# R7FA8D1BH register map
Vendor: Renesas; Series: RA8; File version: 1.2
CPU: CM85 r0p0, little endian, MPU, FPU, VTOR, 4 interrupt priority bits
Registers are 32-bit, read-write, reset 0x0 unless marked. A register's access mark holds for its fields unless they carry their own. Offsets are from the block's base; [hi:lo] are bit positions; {n}, {i} and the like mark numbered series; 'fields as' and 'values as' point back to an identical list.

## xSPI — eXpanded SPI
Base 0x40268000
Same registers: xSPI_NS 0x50268000
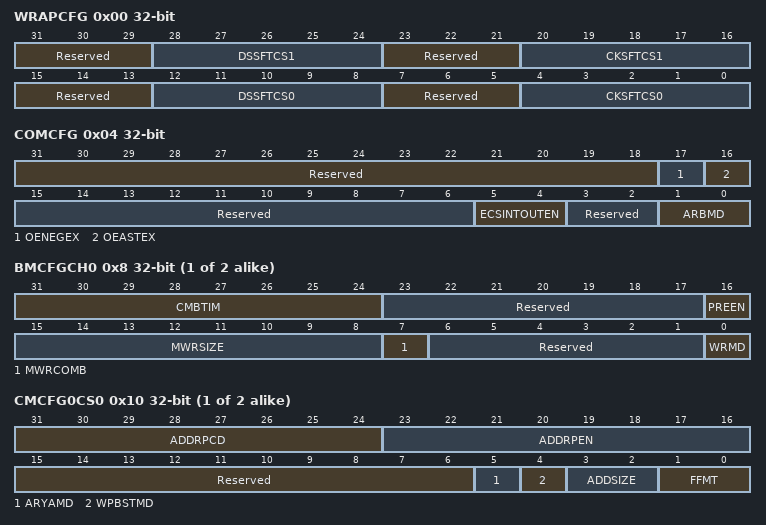
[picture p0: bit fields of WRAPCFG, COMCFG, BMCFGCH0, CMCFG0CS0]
0x00 WRAPCFG — xSPI Wrapper Configuration register
  [31:29] Reserved — These bits are read as 000. The write value should be 000.
  [28:24] DSSFTCS1 — DS shift for slave1
  [23:21] Reserved — These bits are read as 000. The write value should be 000.
  [20:16] CKSFTCS1 — CK shift for slave1
  [15:13] Reserved — These bits are read as 000. The write value should be 000.
  [12:8] DSSFTCS0 — DS shift for slave0
    0=No shift; 1=Add a delay of 1 cell
  [7:5] Reserved — These bits are read as 000. The write value should be 000.
  [4:0] CKSFTCS0 — CK shift for slave0
    0=No shift; 1=Add a delay of 1 cell
0x04 COMCFG — xSPI Common Configuration register
  [31:18] Reserved — These bits are read as 00000000000000. The write value should be 00000000000000.
  [17] OENEGEX — Output Enable Negating extension
    0=No extend 1cycle Output enable; 1=Extend 1cycle Output enable
  [16] OEASTEX — Output Enable Asserting extension
    values as OENEGEX
  [15:6] Reserved — These bits are read as 0000000000. The write value should be 0000000000.
  [5:4] ECSINTOUTEN — ECS/INT Output Enable
  [3:2] Reserved — These bits are read as 00. The write value should be 00.
  [1:0] ARBMD — Channel arbitration mode
{0x8+4i} BMCFGCH{i} (i=0..1) — xSPI Bridge Map Configuration register ch{i}
  [31:24] CMBTIM — Combination timer
    0=00h (means disabling the combination timer. When the timer is)
  [23:17] Reserved — These bits are read as 0000000. The write value should be 0000000.
  [16] PREEN — Prefetch enable
    0=Disable prefetch function; 1=Enable prefetch function
  [15:8] MWRSIZE — Memory Write Size
  [7] MWRCOMB — Memory Write Combination mode
    0=Disable combination mode; 1=Enable combination mode
  [6:1] Reserved — These bits are read as 000000. The write value should be 000000.
  [0] WRMD — AHB Write Response mode
    0=Return response after storing to Internal Write Buffer; 1=Return response after issuing write transaction to xSPI bus
{0x10+0x10*i} CMCFG0CS{i} (i=0..1) — xSPI Command Map Configuration register 0 cs{i}
  [31:24] ADDRPCD — Address Replace Code
  [23:16] ADDRPEN — Address Replace Enable
    0=No replacement (xSPI frame address field is same as AHB address); 1=Replacement
  [15:6] Reserved — These bits are read as 0000000000. The write value should be 0000000000.
  [5] ARYAMD — Array address mode
    0=Normal address mode; 1=Array address mode
  [4] WPBSTMD — Wrapping burst mode
    0=separate xSPI transfer at the wrapping address boundary; 1=not separate xSPI transfer at the wrapping address boundary
  [3:2] ADDSIZE — Address size
    0=1byte (256Byte address space); 1=2byte (64KByte address space)
  [1:0] FFMT — Frame format
    0=Normal format: Command 1byte, Address ADDSIZE, Data up to AHB transaction; 1=8D-8D-8D profile 1.0 format: Command 2byte, Address ADDSIZE, Data up to AHB transaction
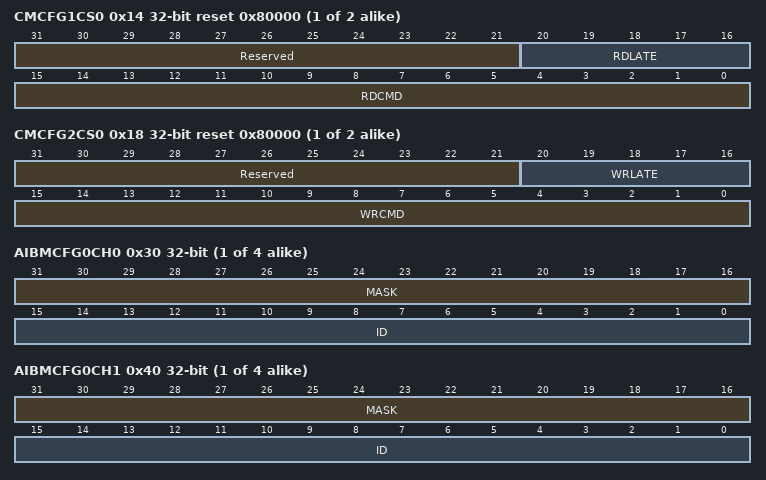
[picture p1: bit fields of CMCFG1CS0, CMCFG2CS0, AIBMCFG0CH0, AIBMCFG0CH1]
{0x14+0x10*i} CMCFG1CS{i} (i=0..1) reset 0x80000 — xSPI Command Map Configuration register 1 cs{i}
  [31:21] Reserved — These bits are read as 00000000000. The write value should be 00000000000.
  [20:16] RDLATE — Read latency cycle
    0=No latency
  [15:0] RDCMD — Read command
{0x18+0x10*i} CMCFG2CS{i} (i=0..1) reset 0x80000 — xSPI Command Map Configuration register 2 cs{i}
  [31:21] Reserved — These bits are read as 00000000000. The write value should be 00000000000.
  [20:16] WRLATE — Write latency cycle
    0=No latency
  [15:0] WRCMD — Write command
{0x30+4i} AIBMCFG{i}CH0 (i=0..3) — xSPI AXI ID Bridge Map Config {i} ch0
  [31:16] MASK — AXI ID to Chx Map Mask
  [15:0] ID — AXI ID to Chx Map Value
{0x40+4i} AIBMCFG{i}CH1 (i=0..3) — xSPI AXI ID Bridge Map Config {i} ch1
  fields as AIBMCFG0CH0
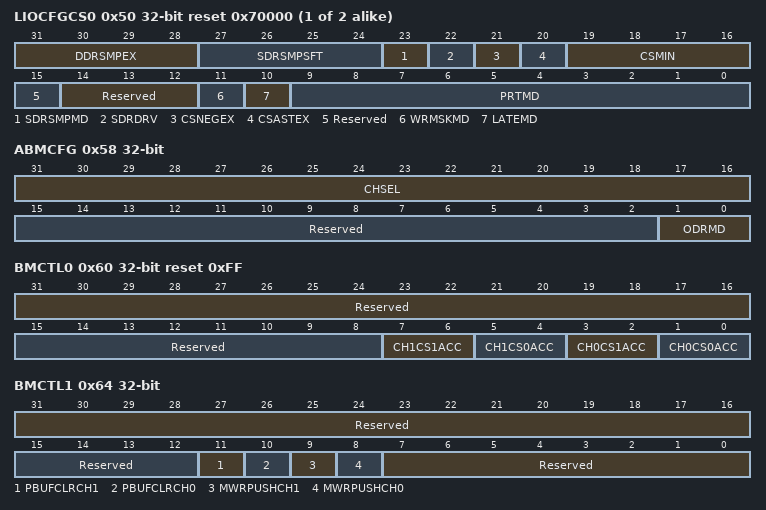
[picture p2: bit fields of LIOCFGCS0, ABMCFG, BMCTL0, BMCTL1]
{0x50+4i} LIOCFGCS{i} (i=0..1) reset 0x70000 — xSPI Link I/O Configuration register cs{i}
  [31:28] DDRSMPEX — DDR sampling window extend
    0=Expand no cycle; 1=Expand 1 cycle; other=others (Reserved)
  [27:24] SDRSMPSFT — SDR Sampling window shift
    0=Sample w/o delay; 1=Sample at 1 cycle delay; other=others (Reserved)
  [23] SDRSMPMD — SDR Sampling mode
    0=Samples data input at falling-edge; 1=Samples data input at rising-edge
  [22] SDRDRV — SDR driving timing
    0=Drive at 1/2 cycle before CK rising-edge; 1=Drive at CK rising-edge
  [21] CSNEGEX — CS negating extension
    0=No extension; 1=Extend 1 cycle
  [20] CSASTEX — CS asserting extension
    0=No extension; 1=Extend 1 cycle
  [19:16] CSMIN — CS minimum idle term
    0=1 cycle
  [15] Reserved — This bit is read as 0. The write value should be 0.
  [14:12] Reserved — These bits are read as 000. The write value should be 000.
  [11] WRMSKMD — Write mask mode
    0=Write mask disable; 1=Write mask enable
  [10] LATEMD — Latency mode
    0=Configurable latency; 1=Variable latency
  [9:0] PRTMD — Protocol mode
    0=0_000_000_000b (1S-1S-1S); 0x3B2=1_110_110_010b (4S-4D-4D); 0x3FF=1_111_111_111b (8D-8D-8D); 0x2FF=1_011_111_111b (8D-8D-8S); 72=0_001_001_000b (1S-2S-2S); 73=0_001_001_001b (2S-2S-2S); 144=0_010_010_000b (1S-4S-4S); 146=0_010_010_010b (4S-4S-4S); other=others (Reserved)
0x58 ABMCFG — xSPI AXI Bridge Map Config
  [31:16] CHSEL — AXI ID to Bridge Channel Select
  [15:2] Reserved — These bits are read as 00000000000000. The write value should be 00000000000000.
  [1:0] ODRMD — AXI Transfer Ordering Mode
0x60 BMCTL0 reset 0xFF — xSPI Bridge Map Control register 0
  [31:16] Reserved — These bits are read as 0000000000000000. The write value should be 0000000000000000.
  [15:8] Reserved — These bits are read as 00000000. The write value should be 00000000.
  [7:6] CH1CS1ACC — System bus ch1 to slave1 memory area access enable
  [5:4] CH1CS0ACC — System bus ch1 to slave0 memory area access enable
  [3:2] CH0CS1ACC — System bus ch0 to slave1 memory area access enable
  [1:0] CH0CS0ACC — System bus ch0 to slave0 memory area access enable
0x64 BMCTL1 wo — xSPI Bridge Map Control register 1
  [31:16] Reserved — The write value should be 0000000000000000.
  [15:12] Reserved — The write value should be 0000.
  [11] PBUFCLRCH1 — Prefetch Buffer clear for ch1
  [10] PBUFCLRCH0 — Prefetch Buffer clear for ch0
    0=No command; 1=Clear request
  [9] MWRPUSHCH1 — Memory Write Data Push for ch1
  [8] MWRPUSHCH0 — Memory Write Data Push for ch0
    0=No command; 1=Push request
  [7:0] Reserved — The write value should be 00000000.
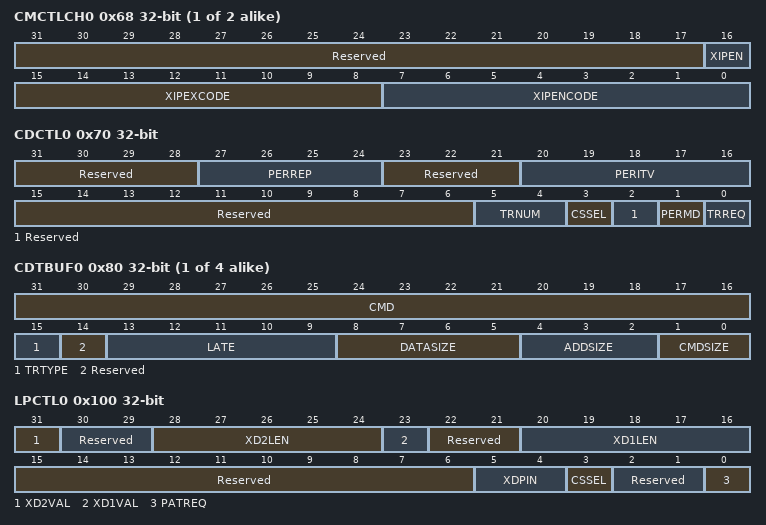
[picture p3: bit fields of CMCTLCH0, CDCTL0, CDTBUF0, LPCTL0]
{0x68+4i} CMCTLCH{i} (i=0..1) — xSPI Command Map Control register ch{i}
  [31:17] Reserved — These bits are read as 000000000000000. The write value should be 000000000000000.
  [16] XIPEN — XiP mode enable
    0=Disable XiP mode; 1=Enable XiP mode
  [15:8] XIPEXCODE — XiP mode exit code
  [7:0] XIPENCODE — XiP mode enter code
0x70 CDCTL0 — xSPI Command Manual Control register 0
  [31:28] Reserved — These bits are read as 0000. The write value should be 0000.
  [27:24] PERREP — Periodic transaction repeat
  [23:21] Reserved — These bits are read as 000. The write value should be 000.
  [20:16] PERITV — Periodic transaction interval
    0=2(=2^1) cycles; 1=4(=2^2) cycles
  [15:6] Reserved — These bits are read as 0000000000. The write value should be 0000000000.
  [5:4] TRNUM — Transaction number
    0=Issue 1 command (using command buffer0); 1=Issue 2 commands (using command buffer0-1)
  [3] CSSEL — Chip select
    0=CS0; 1=CS1
  [2] Reserved — This bit is read as 0. The write value should be 0.
  [1] PERMD — Periodic mode
    0=Direct manual-command mode; 1=Periodic manual-command mode
  [0] TRREQ — Transaction request
    0=No transaction; 1=Request transaction
0x74 CDCTL1 — xSPI Command Manual Control register 1
  [31:0] PEREXP — Periodic transaction expected value
0x78 CDCTL2 — xSPI Command Manual Control register 2
  [31:0] PERMSK — Periodic transaction masked value
{0x80+0x10*i} CDTBUF{i} (i=0..3) — xSPI Command Manual Type buf{i}
  [31:16] CMD — Command (1-2byte)
  [15] TRTYPE — Transaction Type
    0=Read transaction (Readout from memory device); 1=Not read transaction
  [14] Reserved — This bit is read as 0. The write value should be 0.
  [13:9] LATE — Latency cycle
    0=No latency
  [8:5] DATASIZE — Write/Read Data Size
    0=0 byte (No data phase); other=others (Reserved)
  [4:2] ADDSIZE — Address size
    0=0byte (No address phase); other=others (Reserved)
  [1:0] CMDSIZE — Command Size
    0=0byte (No command phase)
{0x84+0x10*i} CDABUF{i} (i=0..3) — xSPI Command Manual Address buf{i}
  [31:0] ADD — Address
{0x88+0x10*i} CDD0BUF{i} (i=0..3) — xSPI Command Manual Data 0 buf{i}
  [31:0] DATA — Write/Read Data
{0x8C+0x10*i} CDD1BUF{i} (i=0..3) — xSPI Command Manual Data 1 buf{i}
  [31:0] DATA — Write/Read Data
0x100 LPCTL0 — xSPI Link Pattern Control register 0
  [31] XD2VAL — XiP Disable pattern 2nd phase value
    0=Low drive; 1=High drive
  [30:29] Reserved — These bits are read as 00. The write value should be 00.
  [28:24] XD2LEN — XiP Disable pattern 2nd phase length
    0=0 cycle
  [23] XD1VAL — XiP Disable pattern 1st phase value
    0=Low drive; 1=High drive
  [22:21] Reserved — These bits are read as 00. The write value should be 00.
  [20:16] XD1LEN — XiP Disable pattern 1st phase length
    0=0 cycle
  [15:6] Reserved — These bits are read as 0000000000. The write value should be 0000000000.
  [5:4] XDPIN — XiP Disable pattern pin
    0=1pin; 1=2pin
  [3] CSSEL — Chip select
    0=slave0 (CS0); 1=slave1 (CS1)
  [2:1] Reserved — These bits are read as 00. The write value should be 00.
  [0] PATREQ — Pattern request
    0=No request XiP Disable pattern; 1=Request XiP Disable pattern
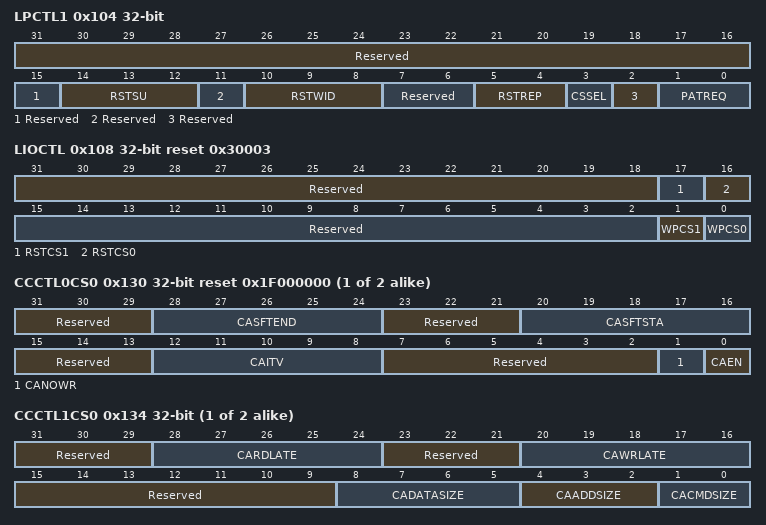
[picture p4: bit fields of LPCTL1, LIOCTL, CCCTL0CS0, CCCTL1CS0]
0x104 LPCTL1 — xSPI Link Pattern Control register 1
  [31:16] Reserved — These bits are read as 0000000000000000. The write value should be 0000000000000000.
  [15] Reserved — This bit is read as 0. The write value should be 0.
  [14:12] RSTSU — Reset pattern data output setup time
    0=1 cycle
  [11] Reserved — This bit is read as 0. The write value should be 0.
  [10:8] RSTWID — Reset pattern width
    0=2(=2^1) cycles; 1=4(=2^2) cycles
  [7:6] Reserved — These bits are read as 00. The write value should be 00.
  [5:4] RSTREP — Reset pattern repeat
    0=4 times (Specified on Reset Signaling Protocol); 1=5 times
  [3] CSSEL — Chip select
    0=slave0 (CS0); 1=slave1 (CS1)
  [2] Reserved — This bit is read as 0. The write value should be 0.
  [1:0] PATREQ — Pattern request
    0=No request; 1=Request Reset pattern; 2=Request CS only pattern
0x108 LIOCTL reset 0x30003 — xSPI Link I/O Control register
  [31:18] Reserved — These bits are read as 00000000000000. The write value should be 00000000000000.
  [17] RSTCS1 — Reset drive for slave1
  [16] RSTCS0 — Reset drive for slave0
    0=Drive Low level; 1=Drive High level
  [15:2] Reserved — These bits are read as 00000000000000. The write value should be 00000000000000.
  [1] WPCS1 — WP drive for slave1
  [0] WPCS0 — WP drive for slave0
    0=Drive Low level; 1=Drive High level
{0x130+0x20*i} CCCTL0CS{i} (i=0..1) reset 0x1F000000 — xSPI Command Calibration Control register 0 cs{i}
  [31:29] Reserved — These bits are read as 000. The write value should be 000.
  [28:24] CASFTEND — Calibration DS shift end value
  [23:21] Reserved — These bits are read as 000. The write value should be 000.
  [20:16] CASFTSTA — Calibration DS shift start value
  [15:13] Reserved — These bits are read as 000. The write value should be 000.
  [12:8] CAITV — Calibration interval
    0=2(=2^1) cycle wait; 1=4(=2^1) cycle wait
  [7:2] Reserved — These bits are read as 000000. The write value should be 000000.
  [1] CANOWR — Calibration no write mode
    0=Calibration sequence with write command; 1=Calibration sequence without write command
  [0] CAEN — Automatic Calibration Enable
    0=Disable automatic calibration; 1=Enable automatic calibration
{0x134+0x20*i} CCCTL1CS{i} (i=0..1) — xSPI Command Calibration Control register 1 cs{i}
  [31:29] Reserved — These bits are read as 000. The write value should be 000.
  [28:24] CARDLATE — Read Latency cycle
    0=No latency
  [23:21] Reserved — These bits are read as 000. The write value should be 000.
  [20:16] CAWRLATE — Write Latency cycle
    0=No latency
  [15:9] Reserved — These bits are read as 0000000. The write value should be 0000000.
  [8:5] CADATASIZE — Write/Read Data Size
    0=1 byte
  [4:2] CAADDSIZE — Address size
    0=0byte (No address phase)
  [1:0] CACMDSIZE — Command Size
    0=0byte (No command phase)
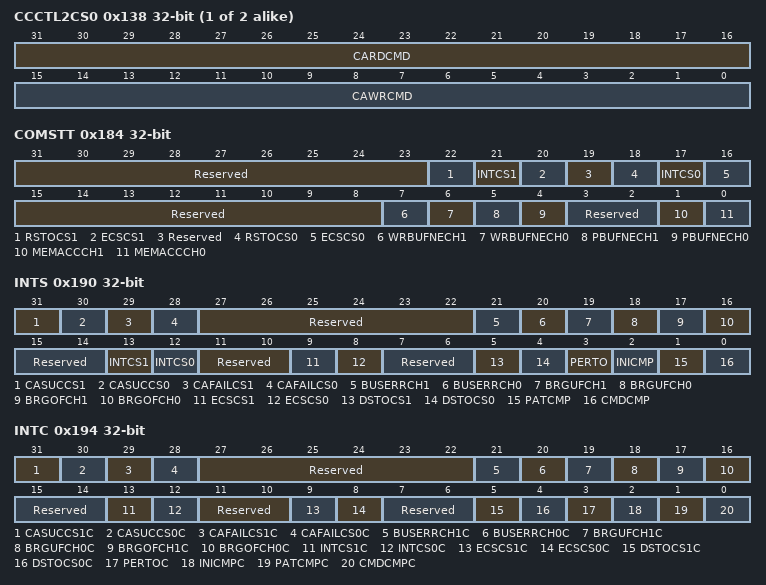
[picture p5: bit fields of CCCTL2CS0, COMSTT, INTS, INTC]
{0x138+0x20*i} CCCTL2CS{i} (i=0..1) — xSPI Command Calibration Control register 2 cs{i}
  [31:16] CARDCMD — Calibration pattern read command
  [15:0] CAWRCMD — Calibration pattern write command
{0x13C+0x20*i} CCCTL3CS{i} (i=0..1) — xSPI Command Calibration Control register 3 cs{i}
  [31:0] CAADD — Calibration pattern address
{0x140+0x20*i} CCCTL4CS{i} (i=0..1) — xSPI Command Calibration Control register 4 cs{i}
  [31:0] CADATA — Calibration pattern data
{0x144+0x20*i} CCCTL5CS{i} (i=0..1) — xSPI Command Calibration Control register 5 cs{i}
  [31:0] CADATA — Calibration pattern data
{0x148+0x20*i} CCCTL6CS{i} (i=0..1) — xSPI Command Calibration Control register 6 cs{i}
  [31:0] CADATA — Calibration pattern data
{0x14C+0x20*i} CCCTL7CS{i} (i=0..1) — xSPI Command Calibration Control register 7 cs{i}
  [31:0] CADATA — Calibration pattern data
0x180 VERSTT ro — xSPI Version register
  [31:0] VER — Version
0x184 COMSTT ro (reset mask 0xFF88FFFF) — xSPI Common Status register
  [31:23] Reserved — These bits are read as 000000000.
  [22] RSTOCS1 — RSTO monitor for slave1
  [21] INTCS1 — INT monitor for slave1
  [20] ECSCS1 — ECS monitor for slave1
  [19] Reserved — This bit is read as 0.
  [18] RSTOCS0 — RSTO monitor for slave0
    0=Low level; 1=High level
  [17] INTCS0 — INT monitor for slave0
    0=Low level; 1=High level
  [16] ECSCS0 — ECS monitor for slave0
    0=Low level; 1=High level
  [15:8] Reserved — These bits are read as 00000000.
  [7] WRBUFNECH1 — Write Buffer Not Empty for ch1
  [6] WRBUFNECH0 — Write Buffer Not Empty for ch0
    0=Empty; 1=Not empty
  [5] PBUFNECH1 — Prefetch Buffer Not Empty for ch1
  [4] PBUFNECH0 — Prefetch Buffer Not Empty for ch0
    0=Empty; 1=Not empty
  [3:2] Reserved — These bits are read as 00.
  [1] MEMACCCH1 — Memory access ongoing from ch1
  [0] MEMACCCH0 — Memory access ongoing from ch0
    0=AHB ch0 is not accessing to memory; 1=AHB ch0 is accessing to memory
{0x188+4i} CASTTCS{i} (i=0..1) ro — xSPI Calibration Status register cs{i}
  [31:0] CASUC — Calibration Success
0x190 INTS ro — xSPI Interrupt Status register
  [31] CASUCCS1 — Calibration success for slave1
  [30] CASUCCS0 — Calibration success for slave0
    0=No detection; 1=Detection
  [29] CAFAILCS1 — Calibration failed for slave1
  [28] CAFAILCS0 — Calibration failed for slave0
    0=No detection; 1=Detection
  [27:22] Reserved — These bits are read as 000000.
  [21] BUSERRCH1 — AHB bus error for CH1
  [20] BUSERRCH0 — AHB bus error for CH0
  [19] BRGUFCH1 — Bridge Buffer underflow for CH1
  [18] BRGUFCH0 — Bridge Buffer underflow for CH0
    0=No detection; 1=Detection
  [17] BRGOFCH1 — Bridge Buffer overflow for CH1
  [16] BRGOFCH0 — Bridge Buffer overflow for CH0
    0=No detection; 1=Detection
  [15:14] Reserved — These bits are read as 00.
  [13] INTCS1 — Interrupt detection for slave1
  [12] INTCS0 — Interrupt detection for slave0
    0=No detection; 1=Detection
  [11:10] Reserved — These bits are read as 00.
  [9] ECSCS1 — ECC error detection for slave1
  [8] ECSCS0 — ECC error detection for slave0
    0=No detection; 1=Detection
  [7:6] Reserved — These bits are read as 00.
  [5] DSTOCS1 — DS timeout for slave1
  [4] DSTOCS0 — DS timeout for slave0
    0=No detection; 1=Detection
  [3] PERTO — Periodic transaction timeout
    0=No detection; 1=Detection
  [2] INICMP — Initial Sequence Completed
    0=No detection; 1=Detection
  [1] PATCMP — Pattern Completed
    0=No detection; 1=Detection
  [0] CMDCMP — Command Completed
    0=No detection; 1=Detection
0x194 INTC wo — xSPI Interrupt Clear register
  [31] CASUCCS1C — Calibration success for slave1 interrupt clear
    0=No change interrupt status; 1=Clear interrupt status
  [30] CASUCCS0C — Calibration success for slave0 interrupt clear
    0=No change interrupt status; 1=Clear interrupt status
  [29] CAFAILCS1C — Calibration failed for slave1 interrupt clear
    0=No change interrupt status; 1=Clear interrupt status
  [28] CAFAILCS0C — Calibration failed for slave0 interrupt clear
    0=No change interrupt status; 1=Clear interrupt status
  [27:22] Reserved — The write value should be 000000.
  [21] BUSERRCH1C — AHB bus error for CH1 interrupt clear
    0=No change interrupt status; 1=Clear interrupt status
  [20] BUSERRCH0C — AHB bus error for CH0 interrupt clear
    0=No change interrupt status; 1=Clear interrupt status
  [19] BRGUFCH1C — Bridge Buffer underflow for CH1 interrupt clear
    0=No change interrupt status; 1=Clear interrupt status
  [18] BRGUFCH0C — Bridge Buffer underflow for CH0 interrupt clear
    0=No change interrupt status; 1=Clear interrupt status
  [17] BRGOFCH1C — Bridge Buffer overflow for CH1 interrupt clear
    0=No change interrupt status; 1=Clear interrupt status
  [16] BRGOFCH0C — Bridge Buffer overflow for CH0 interrupt clear
    0=No change interrupt status; 1=Clear interrupt status
  [15:14] Reserved — The write value should be 00.
  [13] INTCS1C — Interrupt detection for slave1 interrupt clear
    0=No change interrupt status; 1=Clear interrupt status
  [12] INTCS0C — Interrupt detection for slave0 interrupt clear
    0=No change interrupt status; 1=Clear interrupt status
  [11:10] Reserved — The write value should be 00.
  [9] ECSCS1C — ECC error detection for slave1 interrupt clear
    0=No change interrupt status; 1=Clear interrupt status
  [8] ECSCS0C — ECC error detection for slave0 interrupt clear
    0=No change interrupt status; 1=Clear interrupt status
  [7:6] Reserved — The write value should be 00.
  [5] DSTOCS1C — DS timeout for slave1 interrupt clear
    0=No change interrupt status; 1=Clear interrupt status
  [4] DSTOCS0C — DS timeout for slave0 interrupt clear
    0=No change interrupt status; 1=Clear interrupt status
  [3] PERTOC — Periodic transaction timeout interrupt clear
    0=No change interrupt status; 1=Clear interrupt status
  [2] INICMPC — Initial Sequence Completed interrupt clear
    0=No change interrupt status; 1=Clear interrupt status
  [1] PATCMPC — Pattern Completed interrupt clear
    0=No change interrupt status; 1=Clear interrupt status
  [0] CMDCMPC — Command Completed interrupt clear
    0=No change interrupt status; 1=Clear interrupt status
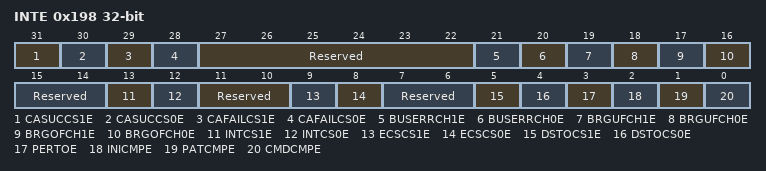
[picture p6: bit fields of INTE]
0x198 INTE — xSPI Interrupt Enable register
  [31] CASUCCS1E — Calibration success for slave1 interrupt enable
    0=Disabled; 1=Enabled
  [30] CASUCCS0E — Calibration success for slave0 interrupt enable
    0=Disabled; 1=Enabled
  [29] CAFAILCS1E — Calibration failed for slave1 interrupt enable
    0=Disabled; 1=Enabled
  [28] CAFAILCS0E — Calibration failed for slave0 interrupt enable
    0=Disabled; 1=Enabled
  [27:22] Reserved — These bits are read as 000000. The write value should be 000000.
  [21] BUSERRCH1E — AHB bus error for CH1 interrupt enable
    0=Disabled; 1=Enabled
  [20] BUSERRCH0E — AHB bus error for CH0 interrupt enable
    0=Disabled; 1=Enabled
  [19] BRGUFCH1E — Bridge Buffer underflow for CH1 interrupt enable
    0=Disabled; 1=Enabled
  [18] BRGUFCH0E — Bridge Buffer underflow for CH0 interrupt enable
    0=Disabled; 1=Enabled
  [17] BRGOFCH1E — Bridge Buffer overflow for CH1 interrupt enable
    0=Disabled; 1=Enabled
  [16] BRGOFCH0E — Bridge Buffer overflow for CH0 interrupt enable
    0=Disabled; 1=Enabled
  [15:14] Reserved — These bits are read as 00. The write value should be 00.
  [13] INTCS1E — Interrupt detection for slave1 interrupt enable
    0=Disabled; 1=Enabled
  [12] INTCS0E — Interrupt detection for slave0 interrupt enable
    0=Disabled; 1=Enabled
  [11:10] Reserved — These bits are read as 00. The write value should be 00.
  [9] ECSCS1E — ECC error detection for slave1 interrupt enable
    0=Disabled; 1=Enabled
  [8] ECSCS0E — ECC error detection for slave0 interrupt enable
    0=Disabled; 1=Enabled
  [7:6] Reserved — These bits are read as 00. The write value should be 00.
  [5] DSTOCS1E — DS timeout for slave1 interrupt enable
    0=Disabled; 1=Enabled
  [4] DSTOCS0E — DS timeout for slave0 interrupt enable
    0=Disabled; 1=Enabled
  [3] PERTOE — Periodic transaction timeout interrupt enable
    0=Disabled; 1=Enabled
  [2] INICMPE — Initial Sequence Completed interrupt enable
    0=Disabled; 1=Enabled
  [1] PATCMPE — Pattern Completed interrupt enable
    0=Disabled; 1=Enabled
  [0] CMDCMPE — Command Completed interrupt enable
    0=Disabled; 1=Enabled
